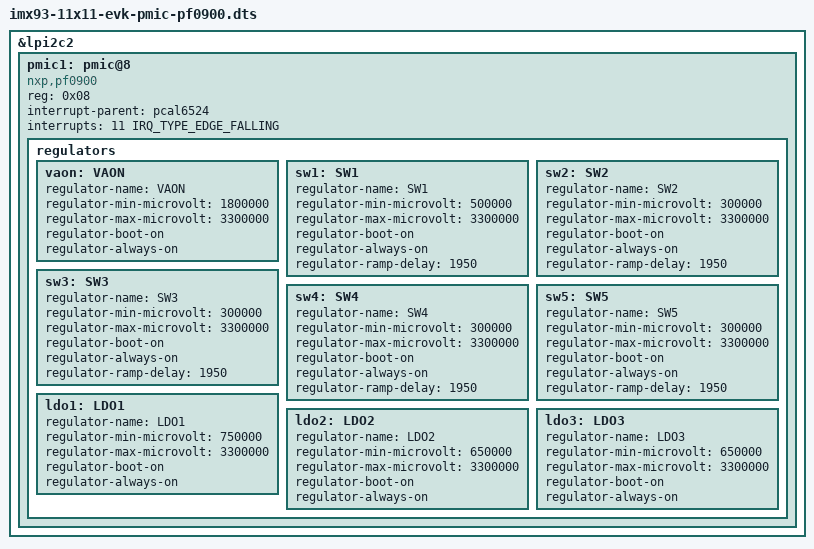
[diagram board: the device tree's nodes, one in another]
// SPDX-License-Identifier: (GPL-2.0+ OR MIT)
/*
 * Copyright 2023 NXP
 */
/dts-v1/;

#include "imx93-11x11-evk.dts"

&lpi2c2 {
	/delete-node/ pmic@25;
	pmic1: pmic@8 {
		compatible = "nxp,pf0900";
		reg = <0x08>;
		interrupt-parent = <&pcal6524>;
		interrupts = <11 IRQ_TYPE_EDGE_FALLING>;
		status = "okay";

		regulators {
			vaon: VAON {
				regulator-name = "VAON";
				regulator-min-microvolt = <1800000>;
				regulator-max-microvolt = <3300000>;
				regulator-boot-on;
				regulator-always-on;
			};

			sw1: SW1 {
				regulator-name = "SW1";
				regulator-min-microvolt = <500000>;
				regulator-max-microvolt = <3300000>;
				regulator-boot-on;
				regulator-always-on;
				regulator-ramp-delay = <1950>;
			};

			sw2: SW2 {
				regulator-name = "SW2";
				regulator-min-microvolt = <300000>;
				regulator-max-microvolt = <3300000>;
				regulator-boot-on;
				regulator-always-on;
				regulator-ramp-delay = <1950>;
			};

			sw3: SW3 {
				regulator-name = "SW3";
				regulator-min-microvolt = <300000>;
				regulator-max-microvolt = <3300000>;
				regulator-boot-on;
				regulator-always-on;
				regulator-ramp-delay = <1950>;
			};

			sw4: SW4{
				regulator-name = "SW4";
				regulator-min-microvolt = <300000>;
				regulator-max-microvolt = <3300000>;
				regulator-boot-on;
				regulator-always-on;
				regulator-ramp-delay = <1950>;
			};

			sw5: SW5{
				regulator-name = "SW5";
				regulator-min-microvolt = <300000>;
				regulator-max-microvolt = <3300000>;
				regulator-boot-on;
				regulator-always-on;
				regulator-ramp-delay = <1950>;
			};

			ldo1: LDO1 {
				regulator-name = "LDO1";
				regulator-min-microvolt = <750000>;
				regulator-max-microvolt = <3300000>;
				regulator-boot-on;
				regulator-always-on;
			};

			ldo2: LDO2 {
				regulator-name = "LDO2";
				regulator-min-microvolt = <650000>;
				regulator-max-microvolt = <3300000>;
				regulator-boot-on;
				regulator-always-on;
			};

			ldo3: LDO3 {
				regulator-name = "LDO3";
				regulator-min-microvolt = <650000>;
				regulator-max-microvolt = <3300000>;
				regulator-boot-on;
				regulator-always-on;
			};
		};
	};

};
